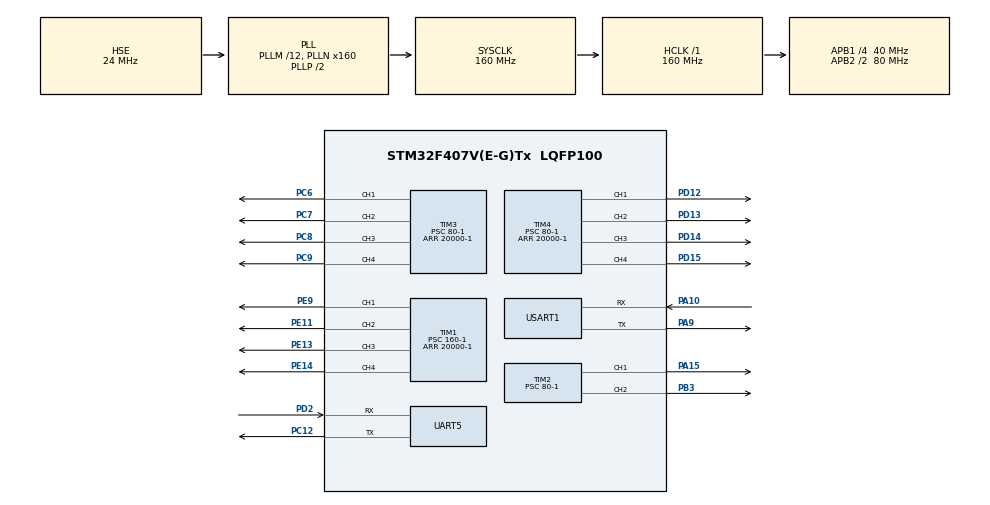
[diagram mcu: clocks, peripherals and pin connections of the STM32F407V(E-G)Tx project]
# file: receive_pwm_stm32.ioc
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Dma.Request0=UART5_RX
Dma.Request1=UART5_TX
Dma.Request2=USART1_RX
Dma.Request3=USART1_TX
Dma.UART5_RX.0.Direction=DMA_PERIPH_TO_MEMORY
Dma.UART5_RX.0.FIFOMode=DMA_FIFOMODE_DISABLE
Dma.UART5_RX.0.Instance=DMA1_Stream0
Dma.UART5_RX.0.MemDataAlignment=DMA_MDATAALIGN_BYTE
Dma.UART5_RX.0.MemInc=DMA_MINC_ENABLE
Dma.UART5_RX.0.Mode=DMA_NORMAL
Dma.UART5_RX.0.PeriphDataAlignment=DMA_PDATAALIGN_BYTE
Dma.UART5_RX.0.PeriphInc=DMA_PINC_DISABLE
Dma.UART5_RX.0.Priority=DMA_PRIORITY_LOW
Dma.UART5_TX.1.Direction=DMA_MEMORY_TO_PERIPH
Dma.UART5_TX.1.FIFOMode=DMA_FIFOMODE_DISABLE
Dma.UART5_TX.1.Instance=DMA1_Stream7
Dma.UART5_TX.1.MemDataAlignment=DMA_MDATAALIGN_BYTE
Dma.UART5_TX.1.MemInc=DMA_MINC_ENABLE
Dma.UART5_TX.1.Mode=DMA_NORMAL
Dma.UART5_TX.1.PeriphDataAlignment=DMA_PDATAALIGN_BYTE
Dma.UART5_TX.1.PeriphInc=DMA_PINC_DISABLE
Dma.UART5_TX.1.Priority=DMA_PRIORITY_LOW
Dma.USART1_RX.2.Direction=DMA_PERIPH_TO_MEMORY
Dma.USART1_RX.2.FIFOMode=DMA_FIFOMODE_DISABLE
Dma.USART1_RX.2.Instance=DMA2_Stream2
Dma.USART1_RX.2.MemDataAlignment=DMA_MDATAALIGN_BYTE
Dma.USART1_RX.2.MemInc=DMA_MINC_ENABLE
Dma.USART1_RX.2.Mode=DMA_NORMAL
Dma.USART1_RX.2.PeriphDataAlignment=DMA_PDATAALIGN_BYTE
Dma.USART1_RX.2.PeriphInc=DMA_PINC_DISABLE
Dma.USART1_RX.2.Priority=DMA_PRIORITY_LOW
Dma.USART1_TX.3.Direction=DMA_MEMORY_TO_PERIPH
Dma.USART1_TX.3.FIFOMode=DMA_FIFOMODE_DISABLE
Dma.USART1_TX.3.Instance=DMA2_Stream7
Dma.USART1_TX.3.MemDataAlignment=DMA_MDATAALIGN_BYTE
Dma.USART1_TX.3.MemInc=DMA_MINC_ENABLE
Dma.USART1_TX.3.Mode=DMA_NORMAL
Dma.USART1_TX.3.PeriphDataAlignment=DMA_PDATAALIGN_BYTE
Dma.USART1_TX.3.PeriphInc=DMA_PINC_DISABLE
Dma.USART1_TX.3.Priority=DMA_PRIORITY_LOW
Mcu.Family=STM32F4
Mcu.Name=STM32F407V(E-G)Tx
Mcu.Package=LQFP100
NVIC.DMA1_Stream0_IRQn=true\:0\:0\:false\:false\:true\:false\:true\:true
NVIC.DMA1_Stream7_IRQn=true\:0\:0\:false\:false\:true\:false\:true\:true
NVIC.DMA2_Stream2_IRQn=true\:0\:0\:false\:false\:true\:false\:true\:true
NVIC.DMA2_Stream7_IRQn=true\:0\:0\:false\:false\:true\:false\:true\:true
NVIC.PriorityGroup=NVIC_PRIORITYGROUP_4
NVIC.UART5_IRQn=true\:0\:0\:false\:false\:true\:false\:true\:true
NVIC.USART1_IRQn=true\:0\:0\:false\:false\:true\:false\:true\:true
PA10.Mode=Asynchronous
PA10.Signal=USART1_RX
PA13.Mode=Serial_Wire
PA13.Signal=SYS_JTMS-SWDIO
PA14.Mode=Serial_Wire
PA14.Signal=SYS_JTCK-SWCLK
PA15.Signal=S_TIM2_CH1_ETR
PA9.Mode=Asynchronous
PA9.Signal=USART1_TX
PB3.Signal=S_TIM2_CH2
PC12.Mode=Asynchronous
PC12.Signal=UART5_TX
PC6.Signal=S_TIM3_CH1
PC7.Signal=S_TIM3_CH2
PC8.Signal=S_TIM3_CH3
PC9.Signal=S_TIM3_CH4
PD12.Signal=S_TIM4_CH1
PD13.Signal=S_TIM4_CH2
PD14.Signal=S_TIM4_CH3
PD15.Signal=S_TIM4_CH4
PD2.Mode=Asynchronous
PD2.Signal=UART5_RX
PE11.Signal=S_TIM1_CH2
PE13.Signal=S_TIM1_CH3
PE14.Signal=S_TIM1_CH4
PE9.Signal=S_TIM1_CH1
PH0-OSC_IN.Mode=HSE-External-Oscillator
PH0-OSC_IN.Signal=RCC_OSC_IN
PH1-OSC_OUT.Mode=HSE-External-Oscillator
PH1-OSC_OUT.Signal=RCC_OSC_OUT
ProjectManager.HeapSize=0x200
ProjectManager.StackSize=0x400
ProjectManager.TargetToolchain=MDK-ARM V5.32
RCC.48MHZClocksFreq_Value=80000000
RCC.AHBFreq_Value=160000000
RCC.APB1CLKDivider=RCC_HCLK_DIV4
RCC.APB1Freq_Value=40000000
RCC.APB1TimFreq_Value=80000000
RCC.APB2CLKDivider=RCC_HCLK_DIV2
RCC.APB2Freq_Value=80000000
RCC.APB2TimFreq_Value=160000000
RCC.CortexFreq_Value=160000000
RCC.HCLKFreq_Value=160000000
RCC.HSE_VALUE=24000000
RCC.HSI_VALUE=16000000
RCC.LSE_VALUE=32768
RCC.PLLM=12
RCC.PLLN=160
RCC.PLLSourceVirtual=RCC_PLLSOURCE_HSE
RCC.SYSCLKFreq_VALUE=160000000
RCC.SYSCLKSource=RCC_SYSCLKSOURCE_PLLCLK
RCC.VCOOutputFreq_Value=320000000
SH.S_TIM1_CH1.0=TIM1_CH1,PWM Generation1 CH1
SH.S_TIM1_CH2.0=TIM1_CH2,PWM Generation2 CH2
SH.S_TIM1_CH3.0=TIM1_CH3,PWM Generation3 CH3
SH.S_TIM1_CH4.0=TIM1_CH4,PWM Generation4 CH4
SH.S_TIM2_CH1_ETR.0=TIM2_CH1,PWM Generation1 CH1
SH.S_TIM2_CH2.0=TIM2_CH2,PWM Generation2 CH2
SH.S_TIM3_CH1.0=TIM3_CH1,PWM Generation1 CH1
SH.S_TIM3_CH2.0=TIM3_CH2,PWM Generation2 CH2
SH.S_TIM3_CH3.0=TIM3_CH3,PWM Generation3 CH3
SH.S_TIM3_CH4.0=TIM3_CH4,PWM Generation4 CH4
SH.S_TIM4_CH1.0=TIM4_CH1,PWM Generation1 CH1
SH.S_TIM4_CH2.0=TIM4_CH2,PWM Generation2 CH2
SH.S_TIM4_CH3.0=TIM4_CH3,PWM Generation3 CH3
SH.S_TIM4_CH4.0=TIM4_CH4,PWM Generation4 CH4
TIM1.Channel-PWM\ Generation1\ CH1=TIM_CHANNEL_1
TIM1.Channel-PWM\ Generation2\ CH2=TIM_CHANNEL_2
TIM1.Channel-PWM\ Generation3\ CH3=TIM_CHANNEL_3
TIM1.Channel-PWM\ Generation4\ CH4=TIM_CHANNEL_4
TIM1.Period=20000-1
TIM1.Prescaler=160-1
TIM2.Channel-PWM\ Generation1\ CH1=TIM_CHANNEL_1
TIM2.Channel-PWM\ Generation2\ CH2=TIM_CHANNEL_2
TIM2.Period=20000-1
TIM2.Prescaler=80-1
TIM3.Channel-PWM\ Generation1\ CH1=TIM_CHANNEL_1
TIM3.Channel-PWM\ Generation2\ CH2=TIM_CHANNEL_2
TIM3.Channel-PWM\ Generation3\ CH3=TIM_CHANNEL_3
TIM3.Channel-PWM\ Generation4\ CH4=TIM_CHANNEL_4
TIM3.Period=20000-1
TIM3.Prescaler=80-1
TIM4.Channel-PWM\ Generation1\ CH1=TIM_CHANNEL_1
TIM4.Channel-PWM\ Generation2\ CH2=TIM_CHANNEL_2
TIM4.Channel-PWM\ Generation3\ CH3=TIM_CHANNEL_3
TIM4.Channel-PWM\ Generation4\ CH4=TIM_CHANNEL_4
TIM4.Period=20000-1
TIM4.Prescaler=80-1
TIM5.Period=5000-1
TIM5.Prescaler=160-1
UART5.VirtualMode=Asynchronous
USART1.VirtualMode=VM_ASYNC
VP_TIM1_VS_ClockSourceINT.Mode=Internal
VP_TIM2_VS_ClockSourceINT.Mode=Internal
VP_TIM3_VS_ClockSourceINT.Mode=Internal
VP_TIM5_VS_ClockSourceINT.Mode=Internal
board=custom

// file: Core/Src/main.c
/* USER CODE BEGIN Header */
/**
  ******************************************************************************
  * @file           : main.c
  * @brief          : Main program body
  ******************************************************************************
  * @attention
  *
  * Copyright (c) 2025 STMicroelectronics.
  * All rights reserved.
  *
  * This software is licensed under terms that can be found in the LICENSE file
  * in the root directory of this software component.
  * If no LICENSE file comes with this software, it is provided AS-IS.
  *
  ******************************************************************************
  */
/* USER CODE END Header */
#include "main.h"
#include "dma.h"
#include "tim.h"
#include "usart.h"
#include "gpio.h"

/* USER CODE BEGIN Includes */
#include "Parse_pwm.h"
#include "Driver_pwm.h"
#include "Uart_service.h"
#include "protocol_v1.h"

/* USER CODE END Includes */

void SystemClock_Config(void);

int main(void)
{

  /* MCU Configuration--------------------------------------------------------*/

  /* Reset of all peripherals, Initializes the Flash interface and the Systick. */
  HAL_Init();

  /* Configure the system clock */
  SystemClock_Config();

  /* Initialize all configured peripherals */
  MX_GPIO_Init();
  MX_DMA_Init();
  MX_TIM1_Init();
  MX_TIM2_Init();
  MX_TIM3_Init();
  MX_TIM4_Init();
  MX_TIM5_Init();
  MX_UART5_Init();
  MX_USART1_UART_Init();
  /* USER CODE BEGIN 2 */
  Driver_PWM_Init();  //初始化PWM通道
  protocol_force_failsafe(); //进入保护状态，所有通道回中位
  protocol_process_init(); //协议处理初始化

  /* USER CODE END 2 */

  /* Infinite loop */
  /* USER CODE BEGIN WHILE */
  while (1)
  {
    //process_uart5_message();

    protocol_process(); //协议处理，在主循环中调用
    protocol_poll();    //协议轮询钩子
    HAL_Delay(1);
    /* USER CODE END WHILE */

  }
}

void SystemClock_Config(void)
{
  RCC_OscInitTypeDef RCC_OscInitStruct = {0};
  RCC_ClkInitTypeDef RCC_ClkInitStruct = {0};

  /** Configure the main internal regulator output voltage
  */
  __HAL_RCC_PWR_CLK_ENABLE();
  __HAL_PWR_VOLTAGESCALING_CONFIG(PWR_REGULATOR_VOLTAGE_SCALE1);

  /** Initializes the RCC Oscillators according to the specified parameters
  * in the RCC_OscInitTypeDef structure.
  */
  RCC_OscInitStruct.OscillatorType = RCC_OSCILLATORTYPE_HSE;
  RCC_OscInitStruct.HSEState = RCC_HSE_ON;
  RCC_OscInitStruct.PLL.PLLState = RCC_PLL_ON;
  RCC_OscInitStruct.PLL.PLLSource = RCC_PLLSOURCE_HSE;
  RCC_OscInitStruct.PLL.PLLM = 12;
  RCC_OscInitStruct.PLL.PLLN = 160;
  RCC_OscInitStruct.PLL.PLLP = RCC_PLLP_DIV2;
  RCC_OscInitStruct.PLL.PLLQ = 4;
  if (HAL_RCC_OscConfig(&RCC_OscInitStruct) != HAL_OK)
  {
    Error_Handler();
  }

  /** Initializes the CPU, AHB and APB buses clocks
  */
  RCC_ClkInitStruct.ClockType = RCC_CLOCKTYPE_HCLK|RCC_CLOCKTYPE_SYSCLK
                              |RCC_CLOCKTYPE_PCLK1|RCC_CLOCKTYPE_PCLK2;
  RCC_ClkInitStruct.SYSCLKSource = RCC_SYSCLKSOURCE_PLLCLK;
  RCC_ClkInitStruct.AHBCLKDivider = RCC_SYSCLK_DIV1;
  RCC_ClkInitStruct.APB1CLKDivider = RCC_HCLK_DIV4;
  RCC_ClkInitStruct.APB2CLKDivider = RCC_HCLK_DIV2;

  if (HAL_RCC_ClockConfig(&RCC_ClkInitStruct, FLASH_LATENCY_5) != HAL_OK)
  {
    Error_Handler();
  }
}

void Error_Handler(void)
{
  __disable_irq();
  while (1)
  {
  }
}
